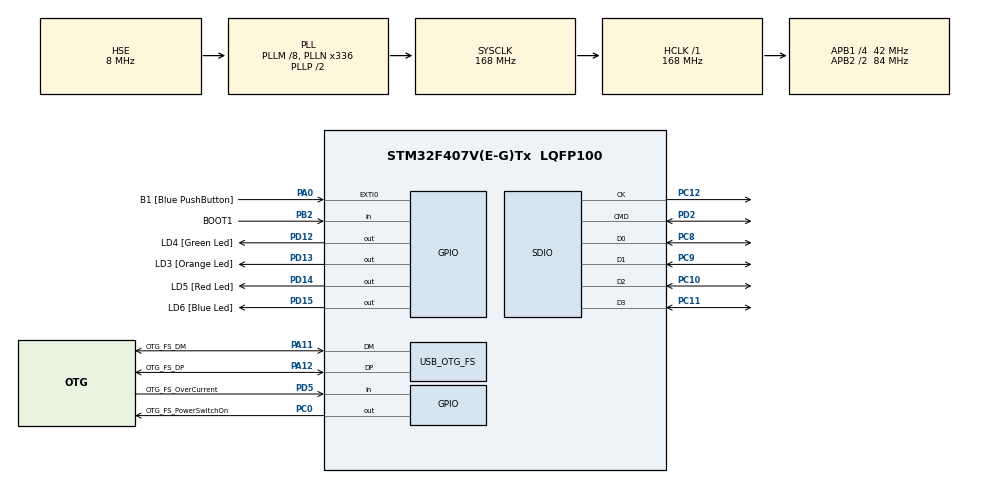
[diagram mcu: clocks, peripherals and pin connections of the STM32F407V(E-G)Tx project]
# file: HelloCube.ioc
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Mcu.Family=STM32F4
Mcu.Name=STM32F407V(E-G)Tx
Mcu.Package=LQFP100
NVIC.OTG_FS_IRQn=true\:0\:0\:false\:false\:true
NVIC.PriorityGroup=NVIC_PRIORITYGROUP_0
PA0-WKUP.GPIO_Label=B1 [Blue PushButton]
PA0-WKUP.Signal=GPXTI0
PA11.GPIO_Label=OTG_FS_DM
PA11.GPIO_Mode=GPIO_MODE_AF_PP
PA11.GPIO_PuPd=GPIO_NOPULL
PA11.GPIO_Speed=GPIO_SPEED_FREQ_LOW
PA11.Mode=Device_Only
PA11.Signal=USB_OTG_FS_DM
PA12.GPIO_Label=OTG_FS_DP
PA12.GPIO_Mode=GPIO_MODE_AF_PP
PA12.GPIO_PuPd=GPIO_NOPULL
PA12.GPIO_Speed=GPIO_SPEED_FREQ_LOW
PA12.Mode=Device_Only
PA12.Signal=USB_OTG_FS_DP
PA13.GPIO_Label=SWDIO
PA13.Mode=Serial_Wire
PA13.Signal=SYS_JTMS-SWDIO
PA14.GPIO_Label=SWCLK
PA14.Mode=Serial_Wire
PA14.Signal=SYS_JTCK-SWCLK
PB2.GPIO_Label=BOOT1
PB2.GPIO_Mode=GPIO_MODE_INPUT
PB2.GPIO_PuPd=GPIO_NOPULL
PB2.Signal=GPIO_Input
PC0.GPIO_Label=OTG_FS_PowerSwitchOn
PC0.GPIO_PuPd=GPIO_NOPULL
PC0.GPIO_Speed=GPIO_SPEED_FREQ_LOW
PC0.PinState=GPIO_PIN_SET
PC0.Signal=GPIO_Output
PC10.Mode=SD_4_bits_Wide_bus
PC10.Signal=SDIO_D2
PC11.Mode=SD_4_bits_Wide_bus
PC11.Signal=SDIO_D3
PC12.Mode=SD_4_bits_Wide_bus
PC12.Signal=SDIO_CK
PC8.Mode=SD_4_bits_Wide_bus
PC8.Signal=SDIO_D0
PC9.Mode=SD_4_bits_Wide_bus
PC9.Signal=SDIO_D1
PD12.GPIO_Label=LD4 [Green Led]
PD12.GPIO_PuPd=GPIO_NOPULL
PD12.GPIO_Speed=GPIO_SPEED_FREQ_LOW
PD12.Signal=GPIO_Output
PD13.GPIO_Label=LD3 [Orange Led]
PD13.GPIO_PuPd=GPIO_NOPULL
PD13.GPIO_Speed=GPIO_SPEED_FREQ_LOW
PD13.Signal=GPIO_Output
PD14.GPIO_Label=LD5 [Red Led]
PD14.GPIO_PuPd=GPIO_NOPULL
PD14.GPIO_Speed=GPIO_SPEED_FREQ_LOW
PD14.Signal=GPIO_Output
PD15.GPIO_Label=LD6 [Blue Led]
PD15.GPIO_PuPd=GPIO_NOPULL
PD15.GPIO_Speed=GPIO_SPEED_FREQ_LOW
PD15.Signal=GPIO_Output
PD2.Mode=SD_4_bits_Wide_bus
PD2.Signal=SDIO_CMD
PD5.GPIO_Label=OTG_FS_OverCurrent
PD5.GPIO_Mode=GPIO_MODE_INPUT
PD5.GPIO_PuPd=GPIO_NOPULL
PD5.Signal=GPIO_Input
PH0-OSC_IN.GPIO_Label=PH0-OSC_IN
PH0-OSC_IN.Mode=HSE-External-Oscillator
PH0-OSC_IN.Signal=RCC_OSC_IN
PH1-OSC_OUT.GPIO_Label=PH1-OSC_OUT
PH1-OSC_OUT.Mode=HSE-External-Oscillator
PH1-OSC_OUT.Signal=RCC_OSC_OUT
ProjectManager.HeapSize=0x5000
ProjectManager.StackSize=0x800
ProjectManager.TargetToolchain=SW4STM32
RCC.48MHZClocksFreq_Value=48000000
RCC.AHBFreq_Value=168000000
RCC.APB1CLKDivider=RCC_HCLK_DIV4
RCC.APB1Freq_Value=42000000
RCC.APB1TimFreq_Value=84000000
RCC.APB2CLKDivider=RCC_HCLK_DIV2
RCC.APB2Freq_Value=84000000
RCC.APB2TimFreq_Value=168000000
RCC.CortexFreq_Value=168000000
RCC.HCLKFreq_Value=168000000
RCC.HSE_VALUE=8000000
RCC.HSI_VALUE=16000000
RCC.LSE_VALUE=32768
RCC.PLLM=8
RCC.PLLN=336
RCC.PLLQ=7
RCC.SYSCLKFreq_VALUE=168000000
RCC.SYSCLKSource=RCC_SYSCLKSOURCE_PLLCLK
RCC.VCOOutputFreq_Value=336000000
USB_DEVICE.CLASS_NAME_FS=MSC
USB_DEVICE.VirtualModeFS=Msc_FS
USB_OTG_FS.VirtualMode=Device_Only
VP_FATFS_VS_Generic.Mode=User_defined
VP_USB_DEVICE_VS_USB_DEVICE_MSC_FS.Mode=MSC_FS
board=STM32F4DISCOVERY

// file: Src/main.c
/**
  ******************************************************************************
  * File Name          : main.c
  * Description        : Main program body
  ******************************************************************************
  *
  * Copyright (c) 2017 STMicroelectronics International N.V.
  * All rights reserved.
  *
  * Redistribution and use in source and binary forms, with or without
  * modification, are permitted, provided that the following conditions are met:
  *
  * 1. Redistribution of source code must retain the above copyright notice,
  *    this list of conditions and the following disclaimer.
  * 2. Redistributions in binary form must reproduce the above copyright notice,
  *    this list of conditions and the following disclaimer in the documentation
  *    and/or other materials provided with the distribution.
  * 3. Neither the name of STMicroelectronics nor the names of other
  *    contributors to this software may be used to endorse or promote products
  *    derived from this software without specific written permission.
  * 4. This software, including modifications and/or derivative works of this
  *    software, must execute solely and exclusively on microcontroller or
  *    microprocessor devices manufactured by or for STMicroelectronics.
  * 5. Redistribution and use of this software other than as permitted under
  *    this license is void and will automatically terminate your rights under
  *    this license.
  *
  * THIS SOFTWARE IS PROVIDED BY STMICROELECTRONICS AND CONTRIBUTORS "AS IS"
  * AND ANY EXPRESS, IMPLIED OR STATUTORY WARRANTIES, INCLUDING, BUT NOT
  * LIMITED TO, THE IMPLIED WARRANTIES OF MERCHANTABILITY, FITNESS FOR A
  * PARTICULAR PURPOSE AND NON-INFRINGEMENT OF THIRD PARTY INTELLECTUAL PROPERTY
  * RIGHTS ARE DISCLAIMED TO THE FULLEST EXTENT PERMITTED BY LAW. IN NO EVENT
  * SHALL STMICROELECTRONICS OR CONTRIBUTORS BE LIABLE FOR ANY DIRECT, INDIRECT,
  * INCIDENTAL, SPECIAL, EXEMPLARY, OR CONSEQUENTIAL DAMAGES (INCLUDING, BUT NOT
  * LIMITED TO, PROCUREMENT OF SUBSTITUTE GOODS OR SERVICES; LOSS OF USE, DATA,
  * OR PROFITS; OR BUSINESS INTERRUPTION) HOWEVER CAUSED AND ON ANY THEORY OF
  * LIABILITY, WHETHER IN CONTRACT, STRICT LIABILITY, OR TORT (INCLUDING
  * NEGLIGENCE OR OTHERWISE) ARISING IN ANY WAY OUT OF THE USE OF THIS SOFTWARE,
  * EVEN IF ADVISED OF THE POSSIBILITY OF SUCH DAMAGE.
  *
  ******************************************************************************
  */
#include "main.h"
#include "stm32f4xx_hal.h"
#include "fatfs.h"
#include "sdio.h"
#include "usb_device.h"
#include "gpio.h"

/* USER CODE BEGIN Includes */
#include "stm32f4_discovery.h"
/* USER CODE END Includes */

/* USER CODE BEGIN PV */
/* Private variables ---------------------------------------------------------*/

extern SD_HandleTypeDef hsd;
/* USER CODE END PV */

void SystemClock_Config(void);
void Error_Handler(void);

/* USER CODE BEGIN PFP */
/* Private function prototypes -----------------------------------------------*/

/* USER CODE END PFP */

/* USER CODE BEGIN 0 */
//SD_HandleTypeDef hsd;
//HAL_SD_CardInfoTypeDef SDCardInfo;
/* USER CODE END 0 */

int main(void)
{

  /* MCU Configuration----------------------------------------------------------*/

  /* Reset of all peripherals, Initializes the Flash interface and the Systick. */
  HAL_Init();

  /* Configure the system clock */
  SystemClock_Config();

  /* Initialize all configured peripherals */
  MX_GPIO_Init();
  MX_USB_DEVICE_Init();
  MX_SDIO_SD_Init();
  //MX_FATFS_Init();

  /* USER CODE BEGIN 2 */
  volatile GPIO_PinState p;
  volatile char buf[1024];
  HAL_StatusTypeDef ret;

  /* USER CODE END 2 */

  /* Infinite loop */
  while (1)
  {

  /* USER CODE BEGIN 3 */
	  HAL_Delay(500);
	  BSP_LED_Toggle(LED3);
	  BSP_LED_Toggle(LED4);
	  BSP_LED_Toggle(LED5);
	  BSP_LED_Toggle(LED6);
	  p = (uint8_t)HAL_GPIO_ReadPin(GPIOA, GPIO_PIN_9);
	  p = p + 0;

	  //ret = HAL_SD_ReadBlocks(&hsd, (uint8_t*)buf, (uint64_t)(0 * 1024), 1, 1000);
  }
  /* USER CODE END 3 */

}

/** System Clock Configuration
*/
void SystemClock_Config(void)
{

  RCC_OscInitTypeDef RCC_OscInitStruct;
  RCC_ClkInitTypeDef RCC_ClkInitStruct;

    /**Configure the main internal regulator output voltage
    */
  __HAL_RCC_PWR_CLK_ENABLE();

  __HAL_PWR_VOLTAGESCALING_CONFIG(PWR_REGULATOR_VOLTAGE_SCALE1);

    /**Initializes the CPU, AHB and APB busses clocks
    */
  RCC_OscInitStruct.OscillatorType = RCC_OSCILLATORTYPE_HSE;
  RCC_OscInitStruct.HSEState = RCC_HSE_ON;
  RCC_OscInitStruct.PLL.PLLState = RCC_PLL_ON;
  RCC_OscInitStruct.PLL.PLLSource = RCC_PLLSOURCE_HSE;
  RCC_OscInitStruct.PLL.PLLM = 8;
  RCC_OscInitStruct.PLL.PLLN = 336;
  RCC_OscInitStruct.PLL.PLLP = RCC_PLLP_DIV2;
  RCC_OscInitStruct.PLL.PLLQ = 7;
  if (HAL_RCC_OscConfig(&RCC_OscInitStruct) != HAL_OK)
  {
    Error_Handler();
  }

    /**Initializes the CPU, AHB and APB busses clocks
    */
  RCC_ClkInitStruct.ClockType = RCC_CLOCKTYPE_HCLK|RCC_CLOCKTYPE_SYSCLK
                              |RCC_CLOCKTYPE_PCLK1|RCC_CLOCKTYPE_PCLK2;
  RCC_ClkInitStruct.SYSCLKSource = RCC_SYSCLKSOURCE_PLLCLK;
  RCC_ClkInitStruct.AHBCLKDivider = RCC_SYSCLK_DIV1;
  RCC_ClkInitStruct.APB1CLKDivider = RCC_HCLK_DIV4;
  RCC_ClkInitStruct.APB2CLKDivider = RCC_HCLK_DIV2;

  if (HAL_RCC_ClockConfig(&RCC_ClkInitStruct, FLASH_LATENCY_5) != HAL_OK)
  {
    Error_Handler();
  }

    /**Configure the Systick interrupt time
    */
  HAL_SYSTICK_Config(HAL_RCC_GetHCLKFreq()/1000);

    /**Configure the Systick
    */
  HAL_SYSTICK_CLKSourceConfig(SYSTICK_CLKSOURCE_HCLK);

  /* SysTick_IRQn interrupt configuration */
  HAL_NVIC_SetPriority(SysTick_IRQn, 0, 0);
}

void Error_Handler(void)
{
  while(1)
  {
  }
}

/************************ (C) COPYRIGHT STMicroelectronics *****END OF FILE****/
